# NAVSS0_NBSS_NB1_MEM_ATTR1_CFG register map
Vendor: Texas Instruments
Peripheral module from a debugger description file (folder J7VCL).
Registers are 32-bit, read-write, reset 0x50 unless marked. A register's access mark holds for its fields unless they carry their own. Offsets are as the file gives them; lines under a group give offsets from that group; [hi:lo] are bit positions; {n}, {i} and the like mark numbered series; 'fields as' and 'values as' point back to an identical list; <NAME> marks a mode.

## NAVSS0_NBSS_NB1_MEM_ATTR1_CFG
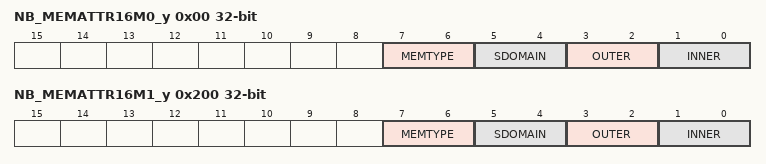
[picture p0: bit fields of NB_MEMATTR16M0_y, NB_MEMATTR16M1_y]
0x00 NB_MEMATTR16M0_y — The Memory Attribute register contains the attributes for all the first 16M mapped regions. Offset = 0h + (y * 4h); where y = 0h to 7Fh
  [7:6] MEMTYPE — This defines the type for the memory. 0h = Device 1h = Writeback 2h = Writethrough 3h = Non-cacheable
  [5:4] SDOMAIN — This defines the shareability domain of the memory. 0h = Non-shared 1h = Inner shared 2h = Outer shared 3h = System shared
  [3:2] OUTER — This defines the outer allocatability of the memory. 0h = Non-allocatable 1h = Writes allocate, reads do not 2h = Reads allocate, writes do not 3h = Reads and writes allocate
  [1:0] INNER — This defines the inner allocatability of the memory. 0h = Non-allocatable 1h = Writes allocate, reads do not 2h = Reads allocate, writes do not 3h = Reads and writes allocate
0x200 NB_MEMATTR16M1_y — The Memory Attribute register contains the attributes for all the second 16M mapped regions. Offset = 200h + (y * 4h); where y = 0h to 1FFFh
  fields as NB_MEMATTR16M0_y
